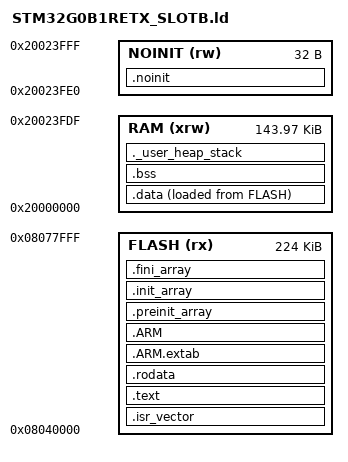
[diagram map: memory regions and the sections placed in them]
/*
******************************************************************************
**
** @file        : STM32G0B1RETX_SLOTB.ld
**
** @author      : Auto-generated by STM32CubeIDE (base), hand-adapted for A/B OTA
**
** @brief       : Linker script for STM32G0B1RETx App SLOT B build (A/B OTA).
**                FLASH is windowed to the 224 KB Slot-B region at 0x08040000
**                (Slot A occupies 0x08008000-0x0803FFFF below it; the
**                boot-config pages sit directly above it at 0x08078000+). RAM's
**                top 32 bytes are carved into a NOINIT region holding the
**                reset-magic word (g_boot_magic) at the SAME physical address
**                the bootloader uses (0x20023FE0) — mirrors boot/g0b1-boot.ld.
**
**                Derived from the CubeIDE-generated STM32G0B1RETX_FLASH.ld;
**                the only changes are the FLASH ORIGIN/LENGTH, the RAM
**                LENGTH, _estack, and the added NOINIT region + .noinit
**                section. Keep in sync with STM32G0B1RETX_SLOTA.ld and
**                boot/g0b1-boot.ld.
**
**  Target      : STMicroelectronics STM32
**
**  Distribution: The file is distributed as is, without any warranty
**                of any kind.
**
******************************************************************************
** @attention
**
** Copyright (c) 2026 STMicroelectronics.
** All rights reserved.
**
** This software is licensed under terms that can be found in the LICENSE file
** in the root directory of this software component.
** If no LICENSE file comes with this software, it is provided AS-IS.
**
******************************************************************************
*/

/* Entry Point */
ENTRY(Reset_Handler)

/* Highest address of the user mode stack — reserve the top 32 B NOINIT
 * region (reset-magic word) below it, same idiom as boot/g0b1-boot.ld. */
_estack = 0x20023FE0;

_Min_Heap_Size = 0x200; /* required amount of heap */
_Min_Stack_Size = 0x400; /* required amount of stack */

/* Memories definition */
MEMORY
{
  RAM    (xrw)    : ORIGIN = 0x20000000,   LENGTH = 0x23FE0
  NOINIT (rw)     : ORIGIN = 0x20023FE0,   LENGTH = 32
  FLASH    (rx)    : ORIGIN = 0x08040000,   LENGTH = 224K
}

/* Sections */
SECTIONS
{

  /* The startup code into "FLASH" Rom type memory */
  .isr_vector :
  {
    . = ALIGN(4);
    KEEP(*(.isr_vector)) /* Startup code */
    . = ALIGN(4);
  } >FLASH

  /* The program code and other data into "FLASH" Rom type memory */
  .text :
  {
    . = ALIGN(4);
    *(.text)           /* .text sections (code) */
    *(.text*)          /* .text* sections (code) */
    *(.glue_7)         /* glue arm to thumb code */
    *(.glue_7t)        /* glue thumb to arm code */
    *(.eh_frame)

    KEEP (*(.init))
    KEEP (*(.fini))

    . = ALIGN(4);
    _etext = .;        /* define a global symbols at end of code */
  } >FLASH

  /* Constant data into "FLASH" Rom type memory */
  .rodata :
  {
    . = ALIGN(4);
    *(.rodata)         /* .rodata sections (constants, strings, etc.) */
    *(.rodata*)        /* .rodata* sections (constants, strings, etc.) */
    . = ALIGN(4);
  } >FLASH

  .ARM.extab (READONLY) : /* The "READONLY" keyword is only supported in GCC11 and later, remove it if using GCC10 or earlier. */
  {
    . = ALIGN(4);
    *(.ARM.extab* .gnu.linkonce.armextab.*)
    . = ALIGN(4);
  } >FLASH

  .ARM (READONLY) : /* The "READONLY" keyword is only supported in GCC11 and later, remove it if using GCC10 or earlier. */
  {
    . = ALIGN(4);
    __exidx_start = .;
    *(.ARM.exidx*)
    __exidx_end = .;
    . = ALIGN(4);
  } >FLASH

  .preinit_array (READONLY) : /* The "READONLY" keyword is only supported in GCC11 and later, remove it if using GCC10 or earlier. */
  {
    . = ALIGN(4);
    PROVIDE_HIDDEN (__preinit_array_start = .);
    KEEP (*(.preinit_array*))
    PROVIDE_HIDDEN (__preinit_array_end = .);
    . = ALIGN(4);
  } >FLASH

  .init_array (READONLY) : /* The "READONLY" keyword is only supported in GCC11 and later, remove it if using GCC10 or earlier. */
  {
    . = ALIGN(4);
    PROVIDE_HIDDEN (__init_array_start = .);
    KEEP (*(SORT(.init_array.*)))
    KEEP (*(.init_array*))
    PROVIDE_HIDDEN (__init_array_end = .);
    . = ALIGN(4);
  } >FLASH

  .fini_array (READONLY) : /* The "READONLY" keyword is only supported in GCC11 and later, remove it if using GCC10 or earlier. */
  {
    . = ALIGN(4);
    PROVIDE_HIDDEN (__fini_array_start = .);
    KEEP (*(SORT(.fini_array.*)))
    KEEP (*(.fini_array*))
    PROVIDE_HIDDEN (__fini_array_end = .);
    . = ALIGN(4);
  } >FLASH

  /* Used by the startup to initialize data */
  _sidata = LOADADDR(.data);

  /* Initialized data sections into "RAM" Ram type memory */
  .data :
  {
    . = ALIGN(4);
    _sdata = .;        /* create a global symbol at data start */
    *(.data)           /* .data sections */
    *(.data*)          /* .data* sections */
    *(.RamFunc)        /* .RamFunc sections */
    *(.RamFunc*)       /* .RamFunc* sections */

    . = ALIGN(4);
    _edata = .;        /* define a global symbol at data end */

  } >RAM AT> FLASH

  /* Uninitialized data section into "RAM" Ram type memory */
  . = ALIGN(4);
  .bss :
  {
    /* This is used by the startup in order to initialize the .bss section */
    _sbss = .;         /* define a global symbol at bss start */
    __bss_start__ = _sbss;
    *(.bss)
    *(.bss*)
    *(COMMON)

    . = ALIGN(4);
    _ebss = .;         /* define a global symbol at bss end */
    __bss_end__ = _ebss;
  } >RAM

  /* Reset-magic word (g_boot_magic) — NOT zeroed by the startup's bss loop
   * (outside [_sbss, _ebss]), and NOT loaded from flash (NOLOAD). Same
   * physical address (0x20023FE0) as boot/g0b1-boot.ld so the app can hand
   * the bootloader a reset-persistent request. */
  .noinit (NOLOAD) :
  {
    . = ALIGN(4);
    *(.noinit)
    *(.noinit*)
    . = ALIGN(4);
  } >NOINIT

  /* User_heap_stack section, used to check that there is enough "RAM" Ram  type memory left */
  ._user_heap_stack :
  {
    . = ALIGN(8);
    PROVIDE ( end = . );
    PROVIDE ( _end = . );
    . = . + _Min_Heap_Size;
    . = . + _Min_Stack_Size;
    . = ALIGN(8);
  } >RAM

  /* Remove information from the compiler libraries */
  /DISCARD/ :
  {
    libc.a ( * )
    libm.a ( * )
    libgcc.a ( * )
  }

  .ARM.attributes 0 : { *(.ARM.attributes) }
}
